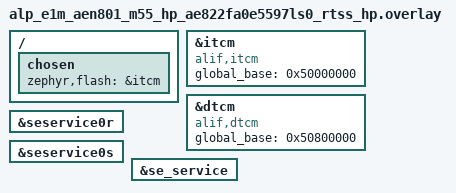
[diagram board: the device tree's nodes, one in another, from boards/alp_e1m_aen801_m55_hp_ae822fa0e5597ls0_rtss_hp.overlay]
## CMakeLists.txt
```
# SPDX-License-Identifier: Apache-2.0
#
# aen-dualcore-master -- the SES-booted core starts the OTHER M55 at runtime via
# the portable alp_mproc_boot_core() (<alp/mproc.h>; the SE boot service backs
# it on AEN -- B1 Option B). Build for BOTH boards; each board's
# fully-qualified boards/<board>.overlay auto-applies (SE mailboxes + per-core
# itcm/dtcm global_base + ITCM retarget). The HP build is the working master on
# E8 (the SES boots the HP entry from a dual ATOC); it releases HE.
cmake_minimum_required(VERSION 3.20)
find_package(Zephyr REQUIRED HINTS $ENV{ZEPHYR_BASE})
project(aen_dualcore_master LANGUAGES C)
target_sources(app PRIVATE src/main.c)
```

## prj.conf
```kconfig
# SPDX-License-Identifier: Apache-2.0
#
# Bench RAM-run config for the E1M-AEN801 (M55-HE). Unlike the single-core
# peripheral examples (which now default to the Alp UART console), the dualcore
# apps deliberately keep the RAM console: both M55 cores are observed through one
# SWD-read buffer (master-agnostic), and a single UART5 can't serve both cores.

# Tier-2 driver Kconfigs (incl. CONFIG_ARM_MHUV2 / CONFIG_HAS_ALIF_SE_SERVICES)
# are gated under ALP_SDK.
CONFIG_ALP_SDK=y

# SE service transport.  CONFIG_ARM_MHUV2 builds the in-tree "arm,mhuv2" IPM
# driver (zephyr/drivers/ipm/ipm_arm_mhuv2.c) and pulls in CONFIG_IPM;
# CONFIG_HAS_ALIF_SE_SERVICES compiles the hal_alif SE client
# (se_services/zephyr/src/se_service.c) the SDK's boot backend consumes -- the
# app itself calls only the portable alp_mproc_boot_core(), and with these two
# on, CONFIG_ALP_SDK_MPROC_BOOT_ALIF_SE defaults y and registers the E8 boot
# backend behind it.  Both are
# `default y` under the relevant DT_HAS_*_ENABLED (the overlay okays the nodes),
# but set them explicitly here so the build is self-describing.
CONFIG_ARM_MHUV2=y
CONFIG_HAS_ALIF_SE_SERVICES=y

# RAM console (no app UART on USB on this bench).
CONFIG_RAM_CONSOLE=y
CONFIG_RAM_CONSOLE_BUFFER_SIZE=2048
CONFIG_UART_CONSOLE=n
CONFIG_CONSOLE=y
CONFIG_PRINTK=y

# Keep the image small + deterministic for a RAM-run. LOG MUST stay off --
# CONFIG_LOG=y reroutes printk into the logging subsystem, which has no
# RAM-console backend, so the RESULT line never reaches 'ram_console_buf'.
CONFIG_LOG=n

# Shared global-SRAM0 mailbox is read/written by BOTH M55 cores, each with its
# own D-cache -> the region must be coherent. Disable the D-cache (the AEN
# SRAM-coherency precedent: the NPU apps do the same) so cross-core reads see
# the other core's writes without explicit clean/invalidate. (A cache-on variant
# would sys_cache_data_flush_range on the writer + invd_range on the reader,
# on silicon where the D-cache can be enabled at all.)
CONFIG_DCACHE=n
```

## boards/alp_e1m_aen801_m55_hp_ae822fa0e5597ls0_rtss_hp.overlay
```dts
/*
 * Copyright (c) 2026 Alp Lab AB
 * SPDX-License-Identifier: Apache-2.0
 *
 * aen-se-service-info overlay for the E1M-AEN801 (Ensemble E8, M55-HE) RAM-run.
 *
 * The SE SERVICE transport nodes live in the E8 SoC overlay
 * (zephyr/dts/alif/ensemble_e8_peripherals.dtsi) status="disabled" by default
 * (they are SoC-fixed: the RTSS-HE <-> SE MHUv2 mailbox pair + the se_service
 * root node).  This overlay just enables them for the RTSS-HE core:
 *   - seservice0r (arm,mhuv2 @ 0x40040000, IRQ 37, "rx") -- SE -> RTSS inbound
 *   - seservice0s (arm,mhuv2 @ 0x40050000, IRQ 38, "tx") -- RTSS -> SE outbound
 *   - se_service  (alif,secure-enclave-services) -- ties the two via phandles
 *
 * No clocks / pinctrl: the MHUv2 mailboxes are core-internal (no pads, no
 * peripheral clock gate); the driver only maps MMIO + wires the IRQ.
 *
 * SCOPE: this proves the transport BINDS (DT_HAS_*_ENABLED + device_is_ready)
 * and issues a zero-risk LCS read (no STOC/fuse/lifecycle write).  See the app
 * header + src/main.c.
 */

/*
 * RAM-run: retarget ROM to ITCM (path-reference form &itcm; the phandle-array
 * form makes FLASH_SIZE=0 and overflows the link) -- the camera-regcheck
 * precedent.
 */
/ {
	chosen {
		zephyr,flash = &itcm;
		/delete-property/ zephyr,code-partition;
	};
};

/*
 * itcm/dtcm `global_base` for local_to_global() -- hal_alif se_service.c puts
 * its outbound SE message buffer through local_to_global() (soc_memory_map.h),
 * which reads DT_PROP(itcm/dtcm, global_base) to translate the M55-local
 * address into the global view the SE's DMA sees.  Upstream Zephyr's
 * arm,itcm/arm,dtcm bindings have no such prop, so re-`compatible` the nodes
 * onto the alp-sdk alif,itcm/alif,dtcm bindings (which declare global_base) and
 * set the E8 RTSS-HE global TCM aliases (ITCM 0x50000000, DTCM 0x50800000),
 * transcribed from the Apache-2.0 zephyr_alif fork ensemble_rtss_he.dtsi -- the
 * same values the NPU + camera + eth local_to_global paths use.
 */
&itcm {
	compatible = "alif,itcm";
	global_base = <0x50000000>;
};

&dtcm {
	compatible = "alif,dtcm";
	global_base = <0x50800000>;
};

&seservice0r {
	status = "okay";
};

&seservice0s {
	status = "okay";
};

&se_service {
	status = "okay";
};
```

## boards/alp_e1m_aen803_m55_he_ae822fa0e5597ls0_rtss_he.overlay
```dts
/*
 * Copyright (c) 2026 Alp Lab AB
 * SPDX-License-Identifier: Apache-2.0
 *
 * aen-se-service-info overlay for the E1M-AEN803 (Ensemble E8, M55-HE) RAM-run.
 *
 * The SE SERVICE transport nodes live in the E8 SoC overlay
 * (zephyr/dts/alif/ensemble_e8_peripherals.dtsi) status="disabled" by default
 * (they are SoC-fixed: the RTSS-HE <-> SE MHUv2 mailbox pair + the se_service
 * root node).  This overlay just enables them for the RTSS-HE core:
 *   - seservice0r (arm,mhuv2 @ 0x40040000, IRQ 37, "rx") -- SE -> RTSS inbound
 *   - seservice0s (arm,mhuv2 @ 0x40050000, IRQ 38, "tx") -- RTSS -> SE outbound
 *   - se_service  (alif,secure-enclave-services) -- ties the two via phandles
 *
 * No clocks / pinctrl: the MHUv2 mailboxes are core-internal (no pads, no
 * peripheral clock gate); the driver only maps MMIO + wires the IRQ.
 *
 * SCOPE: this proves the transport BINDS (DT_HAS_*_ENABLED + device_is_ready)
 * and issues a zero-risk LCS read (no STOC/fuse/lifecycle write).  See the app
 * header + src/main.c.
 */

/*
 * RAM-run: retarget ROM to ITCM (path-reference form &itcm; the phandle-array
 * form makes FLASH_SIZE=0 and overflows the link) -- the aen-adc-regcheck
 * precedent.
 */
/ {
	chosen {
		zephyr,flash = &itcm;
		/delete-property/ zephyr,code-partition;
	};
};

/*
 * itcm/dtcm `global_base` for local_to_global() -- hal_alif se_service.c puts
 * its outbound SE message buffer through local_to_global() (soc_memory_map.h),
 * which reads DT_PROP(itcm/dtcm, global_base) to translate the M55-local
 * address into the global view the SE's DMA sees.  Upstream Zephyr's
 * arm,itcm/arm,dtcm bindings have no such prop, so re-`compatible` the nodes
 * onto the alp-sdk alif,itcm/alif,dtcm bindings (which declare global_base) and
 * set the E8 RTSS-HE global TCM aliases (ITCM 0x58000000, DTCM 0x58800000),
 * transcribed from the Apache-2.0 zephyr_alif fork ensemble_rtss_he.dtsi -- the
 * same values the NPU + camera + eth local_to_global paths use.
 */
&itcm {
	compatible = "alif,itcm";
	global_base = <0x58000000>;
};

&dtcm {
	compatible = "alif,dtcm";
	global_base = <0x58800000>;
};

&seservice0r {
	status = "okay";
};

&seservice0s {
	status = "okay";
};

&se_service {
	status = "okay";
};
```

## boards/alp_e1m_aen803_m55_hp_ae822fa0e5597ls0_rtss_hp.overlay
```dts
/*
 * Copyright (c) 2026 Alp Lab AB
 * SPDX-License-Identifier: Apache-2.0
 *
 * aen-se-service-info overlay for the E1M-AEN803 (Ensemble E8, M55-HE) RAM-run.
 *
 * The SE SERVICE transport nodes live in the E8 SoC overlay
 * (zephyr/dts/alif/ensemble_e8_peripherals.dtsi) status="disabled" by default
 * (they are SoC-fixed: the RTSS-HE <-> SE MHUv2 mailbox pair + the se_service
 * root node).  This overlay just enables them for the RTSS-HE core:
 *   - seservice0r (arm,mhuv2 @ 0x40040000, IRQ 37, "rx") -- SE -> RTSS inbound
 *   - seservice0s (arm,mhuv2 @ 0x40050000, IRQ 38, "tx") -- RTSS -> SE outbound
 *   - se_service  (alif,secure-enclave-services) -- ties the two via phandles
 *
 * No clocks / pinctrl: the MHUv2 mailboxes are core-internal (no pads, no
 * peripheral clock gate); the driver only maps MMIO + wires the IRQ.
 *
 * SCOPE: this proves the transport BINDS (DT_HAS_*_ENABLED + device_is_ready)
 * and issues a zero-risk LCS read (no STOC/fuse/lifecycle write).  See the app
 * header + src/main.c.
 */

/*
 * RAM-run: retarget ROM to ITCM (path-reference form &itcm; the phandle-array
 * form makes FLASH_SIZE=0 and overflows the link) -- the camera-regcheck
 * precedent.
 */
/ {
	chosen {
		zephyr,flash = &itcm;
		/delete-property/ zephyr,code-partition;
	};
};

/*
 * itcm/dtcm `global_base` for local_to_global() -- hal_alif se_service.c puts
 * its outbound SE message buffer through local_to_global() (soc_memory_map.h),
 * which reads DT_PROP(itcm/dtcm, global_base) to translate the M55-local
 * address into the global view the SE's DMA sees.  Upstream Zephyr's
 * arm,itcm/arm,dtcm bindings have no such prop, so re-`compatible` the nodes
 * onto the alp-sdk alif,itcm/alif,dtcm bindings (which declare global_base) and
 * set the E8 RTSS-HE global TCM aliases (ITCM 0x50000000, DTCM 0x50800000),
 * transcribed from the Apache-2.0 zephyr_alif fork ensemble_rtss_he.dtsi -- the
 * same values the NPU + camera + eth local_to_global paths use.
 */
&itcm {
	compatible = "alif,itcm";
	global_base = <0x50000000>;
};

&dtcm {
	compatible = "alif,dtcm";
	global_base = <0x50800000>;
};

&seservice0r {
	status = "okay";
};

&seservice0s {
	status = "okay";
};

&se_service {
	status = "okay";
};
```

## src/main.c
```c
/*
 * Copyright (c) 2026 Alp Lab AB
 * SPDX-License-Identifier: Apache-2.0
 *
 * aen-dualcore-master -- B1 Option B: the SES-booted core starts the OTHER M55
 * at runtime via the portable alp_mproc_boot_core() (<alp/mproc.h>), instead of
 * a dual-boot ATOC (which boots only one core, #200). On this E8 the SES boots
 * the HP entry from a dual ATOC, so the HP build is the master that releases HE.
 *
 * The portable call resolves through the backend registry to the SoM's boot
 * authority -- on AEN that is the Secure Enclave's boot service over the
 * seservice0 MHU (the bench-proven route this example originally validated with
 * a direct vendor call).  Application code carries no vendor include.
 *
 * Board-aware: the HP build boots ALP_CORE_M55_HE @ 0x58000000; the HE build
 * boots ALP_CORE_M55_HP @ 0x50000000. Each stamps its own global-SRAM0 beacon +
 * the boot rc. The partner is the aen-dualcore-probe build for the other core,
 * packaged ["load"]-only (SES loads it but does not auto-boot it).
 *
 * alp_mproc_boot_core() only confirms the boot AUTHORITY accepted the request
 * (see <alp/mproc.h>) -- it says nothing about whether the peer actually came
 * up.  Since both cores' beacons live in the same globally-addressable SRAM0
 * window this app can check that itself: after a successful boot request it
 * polls the peer's own heartbeat word (written by whatever image the peer is
 * running -- aen-dualcore-probe or another aen-dualcore-master) for a bounded
 * window and only claims PASS once that word is observed to move.  This
 * build ships CONFIG_HAS_ALIF_SE_SERVICES=y and no native_sim overlay, so
 * with the DEFAULT config (CONFIG_ALP_SDK_MPROC_BOOT_ALIF_SE_DEFERRED_TOC
 * off) boot_core always resolves to the E8 SE backend's plain
 * se_service_boot_cpu() path for either M55 core (<alp/mproc.h>'s
 * ALP_ERR_NOSUPPORT case -- "no boot authority for core in this build" --
 * is not reachable there); any nonzero rc is a real local error and
 * reported FAIL, not a skippable environment state.
 *
 * The HP build (releasing an HE peer) works with the DEFAULT config --
 * bench-proven fine on 2026-06-17 and 2026-08-01. The HE build (releasing an
 * HP peer) does NOT work with the default config: se_service_boot_cpu()
 * (service 501) is accepted (rc=ALP_OK) but Alif's SE Host Services API docs
 * (v1.109.0 p.115) document that releasing the M55-HP core this way
 * invalidates its TCM, so the peer never comes up and the heartbeat poll
 * below times out -- reported as RESULT SKIP (accepted, peer never
 * advanced), not FAIL: the local request path is fine, the peer just never
 * ran. To make the HE build actually release HP, set
 * CONFIG_ALP_SDK_MPROC_BOOT_ALIF_SE_DEFERRED_TOC_PEER_IS_HP=y (see
 * examples/aen/aen-dualcore-master/testcase.yaml and
 * docs/aen-bench-bringup.md) and flash the peer's ATOC entry
 * ["load","boot","deferred"] instead of ["load"]. With that config ON,
 * ALP_ERR_NOSUPPORT DOES become reachable -- a build whose PEER_IS_HP
 * doesn't match TARGET_CORE (a build-config bug, not a bench/silicon
 * state) now reports RESULT FAIL via the same nonzero-rc check, same as
 * every other real local error.
 */

#include <stdbool.h>
#include <stdint.h>
#include <zephyr/kernel.h>
#include <zephyr/sys/printk.h>

#include <alp/mproc.h>

/* Core-role selection (HP vs HE build of this app), not a peripheral-presence gate. */
#if defined(CONFIG_SOC_AE822FA0E5597LS0_RTSS_HP)
#define ROLE        "HP"
#define TARGET_CORE ALP_CORE_M55_HE
#define TARGET_NAME "M55-HE"
#define TARGET_ADDR 0x58000000U /* HE ITCM global alias = HE-APP loadAddress */
#define SELF_BEACON ((volatile uint32_t *)0x02000010U)
#define BOOT_SLOT   ((volatile uint32_t *)0x02000018U)
#define SELF_MAGIC  0xB1B10090U
#define PEER_BEACON ((volatile uint32_t *)0x02001010U) /* HE's own SELF_BEACON */
#define PEER_MAGIC  0xB1B100E0U
#else
#define ROLE        "HE"
#define TARGET_CORE ALP_CORE_M55_HP
#define TARGET_NAME "M55-HP"
#define TARGET_ADDR 0x50000000U /* HP ITCM global alias = HP-APP loadAddress */
#define SELF_BEACON ((volatile uint32_t *)0x02001010U)
#define BOOT_SLOT   ((volatile uint32_t *)0x02001018U)
#define SELF_MAGIC  0xB1B100E0U
#define PEER_BEACON ((volatile uint32_t *)0x02000010U) /* HP's own SELF_BEACON */
#define PEER_MAGIC  0xB1B10090U
#endif

/* Bounded wait for the released peer's heartbeat to move at least once.
 * Generous vs. a cold M55 boot-to-main(): if the peer never advances within
 * this window on a bench where boot_core reported success, it isn't coming. */
#define PEER_HB_TIMEOUT_MS 2000U
#define PEER_HB_POLL_MS    20U

int main(void)
{
	printk("\n=== aen-dualcore-master (%s) -- start the other M55 via alp_mproc_boot_core ===\n",
	       ROLE);

	SELF_BEACON[0] = SELF_MAGIC;
	SELF_BEACON[1] = 0U;

	alp_status_t rc = alp_mproc_boot_core(TARGET_CORE, TARGET_ADDR);

	BOOT_SLOT[0] = 0xB007C0DEU;
	BOOT_SLOT[1] = (uint32_t)rc;
	printk("alp_mproc_boot_core(%s, 0x%08x) rc=%d\n", TARGET_NAME, TARGET_ADDR, (int)rc);

	if (rc != ALP_OK) {
		printk("RESULT FAIL: alp_mproc_boot_core rc=%d\n", (int)rc);
	} else {
		/* Boot request accepted -- confirm the peer is actually alive by watching
		 * its heartbeat word move, not just trusting the accepted request. */
		uint32_t peer_hb0   = PEER_BEACON[1];
		bool     peer_alive = false;

		for (uint32_t t = 0U; t < PEER_HB_TIMEOUT_MS / PEER_HB_POLL_MS; t++) {
			k_msleep(PEER_HB_POLL_MS);
			if (PEER_BEACON[0] == PEER_MAGIC && PEER_BEACON[1] != peer_hb0) {
				peer_alive = true;
				break;
			}
		}

		if (peer_alive) {
			printk("RESULT PASS: dualcore-master -- %s booted and heartbeating "
			       "(peer beacon magic=0x%08x)\n",
			       TARGET_NAME,
			       PEER_MAGIC);
		} else {
			printk("RESULT SKIP: dualcore-master -- alp_mproc_boot_core(%s) accepted "
			       "(rc=0) but its beacon never advanced within %u ms; local boot "
			       "request OK\n",
			       TARGET_NAME,
			       PEER_HB_TIMEOUT_MS);
		}
	}

	for (uint32_t hb = 1U;; hb++) {
		SELF_BEACON[1] = hb;
		for (volatile uint32_t d = 0U; d < 200000U; d++) {
		}
	}
	return 0;
}
```
